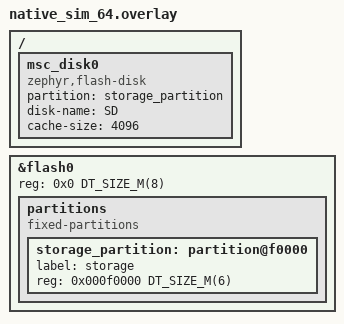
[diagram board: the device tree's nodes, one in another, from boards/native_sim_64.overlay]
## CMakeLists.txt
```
# SPDX-License-Identifier: Apache-2.0

cmake_minimum_required(VERSION 3.20.0)
find_package(Zephyr REQUIRED HINTS $ENV{ZEPHYR_BASE})
project(jpeg_pipeline)

file(GLOB app_sources src/*.c)
target_sources(app PRIVATE ${app_sources})

# Generate MJPEG file to test using GStreamer CLI
find_program(GST_LAUNCH gst-launch-1.0 REQUIRED)

set(TEST_MJPEG_FILE ${ZEPHYR_BINARY_DIR}/include/generated/test.mjpeg)

add_custom_command(
    OUTPUT ${TEST_MJPEG_FILE}
    COMMAND ${GST_LAUNCH}
    videotestsrc num-buffers=${CONFIG_MJPEG_NUM_FRAMES}
    ! videoconvert
    ! "video/x-raw,format=I420,width=${CONFIG_JPEG_IMAGE_WIDTH},height=${CONFIG_JPEG_IMAGE_HEIGHT}"
    ! timeoverlay font-desc="Sans 32"
    ! jpegenc
    ! filesink location=${TEST_MJPEG_FILE}
    COMMENT "Generating test.mjpeg (${CONFIG_JPEG_IMAGE_WIDTH}x${CONFIG_JPEG_IMAGE_HEIGHT}, ${CONFIG_MJPEG_NUM_FRAMES} frames) using GStreamer"
)

add_custom_target(gen_test_mjpeg DEPENDS ${TEST_MJPEG_FILE})

generate_inc_file_for_target(app
    ${TEST_MJPEG_FILE}
    ${ZEPHYR_BINARY_DIR}/include/generated/mjpeg.inc
)

add_dependencies(app gen_test_mjpeg)
```

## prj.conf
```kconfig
CONFIG_LOG=y

# main() mounts the filesystem and writes the input file before starting the
# pipeline, which the default main stack does not cover.
CONFIG_MAIN_STACK_SIZE=2048

CONFIG_MPIPE=y
CONFIG_MPIPE_STRUCTURE_MAX_FIELDS=3
CONFIG_MPIPE_BASE=y
CONFIG_MPIPE_BASE_CAPS_FILTER=y
CONFIG_MPIPE_FS=y
CONFIG_MPIPE_IMG=y
CONFIG_MPIPE_DISP=y
CONFIG_MPIPE_PLAYER=y
# At the parser, we need simultaneously 1 input + 1 output + 1 partial (for next frame) buffers
CONFIG_MPIPE_NET_BUF_POOL_COUNT=3
# Largest estimated size for 320x240 JPEG image
CONFIG_MPIPE_IMG_JPEG_PARSER_MAX_FRAME_SIZE=153600

CONFIG_FILE_SYSTEM=y
CONFIG_FAT_FILESYSTEM_ELM=y
CONFIG_FS_FATFS_LFN=y
CONFIG_FS_FATFS_MAX_LFN=255
CONFIG_DISK_ACCESS=y
CONFIG_DISK_DRIVERS=y

# The bus carries end-of-stream and errors, never data: it needs neither
# zbus priority boost nor zbus logging of its own.
CONFIG_ZBUS_PRIORITY_BOOST=n
CONFIG_ZBUS_LOG_LEVEL_ERR=y
```

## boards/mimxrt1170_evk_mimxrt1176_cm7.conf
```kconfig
CONFIG_MCUX_ELCDIF_FB_NUM=1

CONFIG_VIDEO_BUFFER_POOL_NUM_MAX=2
CONFIG_VIDEO_BUFFER_POOL_HEAP_SIZE=307600
CONFIG_VIDEO_ROTATION_ANGLE=90

CONFIG_MPIPE_VID=y
CONFIG_MPIPE_VID_CONVERT=y
CONFIG_MPIPE_IMG_JPEG_DECODER=y
```

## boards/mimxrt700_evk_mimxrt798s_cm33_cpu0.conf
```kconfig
CONFIG_DCACHE=n
# 3 (jpeg decoder: 2 input + 1 output) + 1 (video converter output)
CONFIG_VIDEO_BUFFER_POOL_NUM_MAX=4
# Resolution: 320x240, Format: NV12 + RGB565 + 2 * JPEG + alignment = 320 * 240 * (1.5 + 2 + 2 * 2) + alignment
CONFIG_VIDEO_BUFFER_POOL_HEAP_SIZE=620000
CONFIG_VIDEO_BUFFER_POOL_ZEPHYR_REGION=y
CONFIG_VIDEO_BUFFER_POOL_ZEPHYR_REGION_NAME="SRAM1"

CONFIG_MPIPE_VID=y
CONFIG_MPIPE_VID_CONVERT=y
```

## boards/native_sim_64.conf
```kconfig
# Flash-backed FAT volume (disk-name "SD") for native_sim
CONFIG_FLASH_SIMULATOR=y
CONFIG_DISK_DRIVER_FLASH=y

# Bind the native PTY UART to stdin/stdout so the shell reads keystrokes typed
# on the launching terminal (otherwise the shell sits on a separate PTY and the
# p/s/r/q commands never receive input).
CONFIG_UART_NATIVE_PTY_0_ON_STDINOUT=y

# Log directly to stdout via the native backend, which is active from boot so
# the boot banner and early log lines (before the shell is up) are printed.
# Disable the shell log backend so those same lines are not printed a second
# time once the shell starts.
CONFIG_LOG_BACKEND_NATIVE_POSIX=y
CONFIG_SHELL_LOG_BACKEND=n

# Threads on native_sim run on host stacks, so this size is never used and
# only reserves memory.
CONFIG_MPIPE_PLAYER_WORKER_STACK_SIZE=64

# native_sim has no JPEG decoder block: decode in software with the jpegdec module.
CONFIG_MPIPE_IMG_JPEG_DECODER=y
```

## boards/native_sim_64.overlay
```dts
/*
 * Copyright (c) 2023 Nordic Semiconductor ASA
 * Copyright (c) 2025 Muhammad Waleed Badar
 * Copyright 2026 NXP
 *
 * SPDX-License-Identifier: Apache-2.0
 */

/delete-node/ &storage_partition;

&flash0 {
	/* Increase flash so we have room for a FAT volume with an MJPEG sample */
	reg = <0x0 DT_SIZE_M(8)>;

	partitions {
		compatible = "fixed-partitions";
		#address-cells = <1>;
		#size-cells = <1>;

		storage_partition: partition@f0000 {
			label = "storage";
			reg = <0x000f0000 DT_SIZE_M(6)>;
		};
	};
};

/ {
	msc_disk0 {
		status = "okay";
		compatible = "zephyr,flash-disk";
		partition = <&storage_partition>;
		disk-name = "SD";
		cache-size = <4096>;
	};
};
```

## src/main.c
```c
/*
 * Copyright 2026 NXP
 *
 * SPDX-License-Identifier: Apache-2.0
 */

#include <errno.h>
#if defined(CONFIG_FAT_FILESYSTEM_ELM)
#include <ff.h>
#endif

#include <zephyr/drivers/video.h>
#include <zephyr/video/controls.h>
#include <zephyr/fs/fs.h>
#include <zephyr/logging/log.h>

#include <zephyr/mpipe/mpipe.h>
#include <zephyr/mpipe/base/mpipe_caps_filter.h>
#include <zephyr/mpipe/disp/mpipe_disp_sink.h>
#include <zephyr/mpipe/fs/mpipe_file_src.h>
#include <zephyr/mpipe/img/mpipe_img_jpeg_parser.h>
#include <zephyr/mpipe/utils/mpipe_player.h>
#if DT_HAS_CHOSEN(zephyr_jpegdec) || DT_HAS_CHOSEN(zephyr_videotrans)
#include <zephyr/mpipe/vid/mpipe_vid_transform.h>
#endif
#if DT_HAS_CHOSEN(zephyr_jpegdec)
#include <zephyr/mpipe/vid/mpipe_vid_convert.h>
#elif defined(CONFIG_MPIPE_IMG_JPEG_DECODER)
#include <zephyr/mpipe/img/mpipe_img_jpeg_decoder.h>
#else
#error "jpeg_dec needs a zephyr,jpegdec device or CONFIG_MPIPE_IMG_JPEG_DECODER"
#endif

LOG_MODULE_REGISTER(main, CONFIG_LOG_DEFAULT_LEVEL);

/* Element IDs (values are arbitrary; only uniqueness within the pipeline matters) */
enum {
	PIPE_ID,
	FILE_SRC_ID,
	JPEG_PARSER_ID,
	CAPS_FILTER_ID,
	JPEG_DEC_ID,
	VID_CONV_ID,
	VID_TRANS_ID,
	DISP_SINK_ID,
};

#define MNT_POINT "/SD:"

#if defined(CONFIG_FAT_FILESYSTEM_ELM)
static FATFS fat_fs;
#endif

static struct fs_mount_t mp = {
	.type = FS_FATFS,
#if defined(CONFIG_FAT_FILESYSTEM_ELM)
	.fs_data = &fat_fs,
#endif
	.mnt_point = MNT_POINT,
};

static const uint8_t mjpeg[] = {
#include "mjpeg.inc"
};
static const size_t mjpeg_sz = sizeof(mjpeg);

static int embed_test_file(void)
{
	struct fs_dirent ent;
	int ret = fs_stat(CONFIG_FILE_INPUT_PATH, &ent);

	if (ret == 0) {
		/* A file of the same size is assumed to be the embedded one: keep it */
		if (mjpeg_sz == 0 || ent.size == mjpeg_sz) {
			return 0;
		}

		LOG_INF("%s is %u bytes, embedded file is %u bytes: replacing it",
			CONFIG_FILE_INPUT_PATH, (unsigned int)ent.size, (unsigned int)mjpeg_sz);
	} else if (ret != -ENOENT) {
		LOG_ERR("fs_stat(%s) failed (%d)", CONFIG_FILE_INPUT_PATH, ret);
		return ret;
	} else if (mjpeg_sz == 0) {
		LOG_ERR("MJPEG test file not available");
		return -ENOENT;
	}

	struct fs_file_t f;

	fs_file_t_init(&f);

	ret = fs_open(&f, CONFIG_FILE_INPUT_PATH, FS_O_CREATE | FS_O_WRITE | FS_O_TRUNC);
	if (ret != 0) {
		LOG_ERR("fs_open(%s) failed (%d)", CONFIG_FILE_INPUT_PATH, ret);
		return ret;
	}

	ssize_t w = fs_write(&f, mjpeg, mjpeg_sz);

	if (w < 0 || (size_t)w != mjpeg_sz) {
		LOG_ERR("fs_write failed (%d)", (int)w);
		(void)fs_close(&f);
		return (w < 0) ? (int)w : -EIO;
	}

	(void)fs_close(&f);

	LOG_INF("Created %s file for test (%u bytes)", CONFIG_FILE_INPUT_PATH,
		(unsigned int)mjpeg_sz);

	return 0;
}

static int mount_sd(void)
{
	int ret;

	ret = fs_mount(&mp);
	if (ret != 0) {
		LOG_ERR("fs_mount failed (%d)", ret);
		return ret;
	}

	LOG_INF("SDCard mounted at %s", MNT_POINT);

	ret = embed_test_file();
	if (ret != 0) {
		return ret;
	}

	return 0;
}

static struct mpipe pipe;
static struct mpipe_file_src file_src;
static struct mpipe_img_jpeg_parser jpeg_parser;
static struct mpipe_caps_filter caps_filter;
static struct mpipe_disp_sink disp_sink;
#if DT_HAS_CHOSEN(zephyr_jpegdec)
static struct mpipe_vid_transform jpeg_dec;
static struct mpipe_vid_convert vid_conv;
#else
static struct mpipe_img_jpeg_decoder jpeg_dec;
#endif
#if DT_HAS_CHOSEN(zephyr_videotrans)
static struct mpipe_vid_transform vid_trans;
#endif
static struct mpipe_player player;

int main(void)
{
	int ret = mount_sd();

	if (ret != 0) {
		goto err;
	}

	ret = mpipe_pipeline_init(&pipe, PIPE_ID);
	if (ret < 0) {
		goto err;
	}
	ret = mpipe_file_src_init(&file_src, FILE_SRC_ID);
	if (ret < 0) {
		goto err;
	}
	ret = mpipe_img_jpeg_parser_init(&jpeg_parser, JPEG_PARSER_ID);
	if (ret < 0) {
		goto err;
	}
	ret = mpipe_caps_filter_init(&caps_filter, CAPS_FILTER_ID);
	if (ret < 0) {
		goto err;
	}
	ret = mpipe_disp_sink_init(&disp_sink, DISP_SINK_ID);
	if (ret < 0) {
		goto err;
	}

#if DT_HAS_CHOSEN(zephyr_jpegdec)
	ret = mpipe_vid_transform_init(&jpeg_dec, JPEG_DEC_ID);
	if (ret < 0) {
		goto err;
	}
	ret = mpipe_vid_convert_init(&vid_conv, VID_CONV_ID);
	if (ret < 0) {
		goto err;
	}

	ret = mpipe_object_set_properties((struct mpipe_object *)&jpeg_dec, MPIPE_PROP_VID_DEVICE,
					  DEVICE_DT_GET_OR_NULL(DT_CHOSEN(zephyr_jpegdec)),
					  MPIPE_PROP_LIST_END);
	if (ret < 0) {
		goto err;
	}
#else
	ret = mpipe_img_jpeg_decoder_init(&jpeg_dec, JPEG_DEC_ID);
	if (ret < 0) {
		goto err;
	}
#endif
#if DT_HAS_CHOSEN(zephyr_videotrans)
	ret = mpipe_vid_transform_init(&vid_trans, VID_TRANS_ID);
	if (ret < 0) {
		goto err;
	}
	ret = mpipe_object_set_properties(
		(struct mpipe_object *)&vid_trans,
		COND_CODE_0(CONFIG_VIDEO_ROTATION_ANGLE,
			(), (VIDEO_CID_ROTATE, CONFIG_VIDEO_ROTATION_ANGLE,))
								   MPIPE_PROP_LIST_END);
	if (ret < 0) {
		goto err;
	}
#endif

	ret = mpipe_object_set_properties((struct mpipe_object *)&file_src, MPIPE_PROP_FS_SRC_PATH,
					  CONFIG_FILE_INPUT_PATH, MPIPE_PROP_LIST_END);
	if (ret < 0) {
		goto err;
	}

	{
		struct mpipe_structure caps;

		ret = mpipe_structure_init_fields(
			&caps, MPIPE_MEDIA_VIDEO, MPIPE_CAPS_PIXEL_FORMAT, MPIPE_TYPE_UINT,
			VIDEO_PIX_FMT_JPEG, MPIPE_CAPS_IMAGE_WIDTH, MPIPE_TYPE_UINT,
			CONFIG_JPEG_IMAGE_WIDTH, MPIPE_CAPS_IMAGE_HEIGHT, MPIPE_TYPE_UINT,
			CONFIG_JPEG_IMAGE_HEIGHT, MPIPE_CAPS_END);

		if (ret != 0) {
			goto err;
		}

		ret = mpipe_object_set_properties((struct mpipe_object *)&caps_filter,
						  MPIPE_PROP_BASE_CAPS_FILTER_CAPS, &caps,
						  MPIPE_PROP_LIST_END);
		if (ret < 0) {
			goto err;
		}
	}

	/* clang-format off */
	ret = mpipe_bin_add((struct mpipe_bin *)&pipe,
			(struct mpipe_element *)&file_src,
			(struct mpipe_element *)&jpeg_parser,
			(struct mpipe_element *)&caps_filter,
			(struct mpipe_element *)&jpeg_dec,
			IF_ENABLED(DT_HAS_CHOSEN(zephyr_jpegdec),
				   ((struct mpipe_element *)&vid_conv,))
			IF_ENABLED(DT_HAS_CHOSEN(zephyr_videotrans),
				   ((struct mpipe_element *)&vid_trans,))
			(struct mpipe_element *)&disp_sink,
			NULL);
	if (ret < 0) {
		LOG_ERR("Failed to add elements (%d)", ret);
		goto err;
	}

	ret = mpipe_element_link((struct mpipe_element *)&file_src,
			(struct mpipe_element *)&jpeg_parser,
			(struct mpipe_element *)&caps_filter,
			(struct mpipe_element *)&jpeg_dec,
			IF_ENABLED(DT_HAS_CHOSEN(zephyr_jpegdec),
				   ((struct mpipe_element *)&vid_conv,))
			IF_ENABLED(DT_HAS_CHOSEN(zephyr_videotrans),
				   ((struct mpipe_element *)&vid_trans,))
			(struct mpipe_element *)&disp_sink,
			NULL);
	if (ret < 0) {
		LOG_ERR("Failed to link elements (%d)", ret);
		goto err;
	}
	/* clang-format on */

	LOG_INF("Pipeline linked.");

	ret = mpipe_player_init(&player, &pipe);
	if (ret != 0) {
		LOG_ERR("Failed to init player (%d)", ret);
		goto err;
	}

	(void)mpipe_player_play(&player);
	(void)mpipe_player_wait_quit(&player);
	(void)mpipe_player_deinit(&player);

	ret = fs_unmount(&mp);
	if (ret != 0) {
		LOG_ERR("fs_unmount failed (%d)", ret);
	}

	LOG_INF("Done.");

	return 0;

err:
	LOG_ERR("Aborting sample");
	return 0;
}
```
